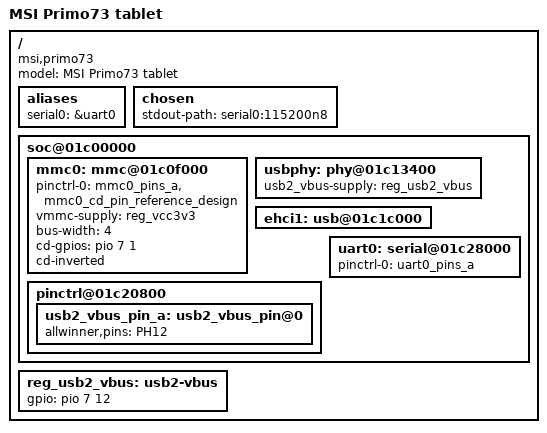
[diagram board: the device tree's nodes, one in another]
/*
 * Copyright 2014 Siarhei Siamashka <siarhei.siamashka@xxxxxxxxx>
 *
 * This file is dual-licensed: you can use it either under the terms
 * of the GPL or the X11 license, at your option. Note that this dual
 * licensing only applies to this file, and not this project as a
 * whole.
 *
 *  a) This library is free software; you can redistribute it and/or
 *     modify it under the terms of the GNU General Public License as
 *     published by the Free Software Foundation; either version 2 of the
 *     License, or (at your option) any later version.
 *
 *     This library is distributed in the hope that it will be useful,
 *     but WITHOUT ANY WARRANTY; without even the implied warranty of
 *     MERCHANTABILITY or FITNESS FOR A PARTICULAR PURPOSE.  See the
 *     GNU General Public License for more details.
 *
 *     You should have received a copy of the GNU General Public
 *     License along with this library; if not, write to the Free
 *     Software Foundation, Inc., 51 Franklin St, Fifth Floor, Boston,
 *     MA 02110-1301 USA
 *
 * Or, alternatively,
 *
 *  b) Permission is hereby granted, free of charge, to any person
 *     obtaining a copy of this software and associated documentation
 *     files (the "Software"), to deal in the Software without
 *     restriction, including without limitation the rights to use,
 *     copy, modify, merge, publish, distribute, sublicense, and/or
 *     sell copies of the Software, and to permit persons to whom the
 *     Software is furnished to do so, subject to the following
 *     conditions:
 *
 *     The above copyright notice and this permission notice shall be
 *     included in all copies or substantial portions of the Software.
 *
 *     THE SOFTWARE IS PROVIDED "AS IS", WITHOUT WARRANTY OF ANY KIND,
 *     EXPRESS OR IMPLIED, INCLUDING BUT NOT LIMITED TO THE WARRANTIES
 *     OF MERCHANTABILITY, FITNESS FOR A PARTICULAR PURPOSE AND
 *     NONINFRINGEMENT. IN NO EVENT SHALL THE AUTHORS OR COPYRIGHT
 *     HOLDERS BE LIABLE FOR ANY CLAIM, DAMAGES OR OTHER LIABILITY,
 *     WHETHER IN AN ACTION OF CONTRACT, TORT OR OTHERWISE, ARISING
 *     FROM, OUT OF OR IN CONNECTION WITH THE SOFTWARE OR THE USE OR
 *     OTHER DEALINGS IN THE SOFTWARE.
 */

/dts-v1/;
#include "sun7i-a20.dtsi"
#include "sunxi-common-regulators.dtsi"

/ {
	model = "MSI Primo73 tablet";
	compatible = "msi,primo73", "allwinner,sun7i-a20";

	aliases {
		serial0 = &uart0;
	};

	chosen {
		stdout-path = "serial0:115200n8";
	};

	soc@01c00000 {
		mmc0: mmc@01c0f000 {
			pinctrl-names = "default";
			pinctrl-0 = <&mmc0_pins_a>, <&mmc0_cd_pin_reference_design>;
			vmmc-supply = <&reg_vcc3v3>;
			bus-width = <4>;
			cd-gpios = <&pio 7 1 0>; /* PH1 */
			cd-inverted;
			status = "okay";
		};

		usbphy: phy@01c13400 {
			usb2_vbus-supply = <&reg_usb2_vbus>;
			status = "okay";
		};

		ehci1: usb@01c1c000 {
			/* rtl8188etv wifi is connected here */
			status = "okay";
		};

		pinctrl@01c20800 {
			usb2_vbus_pin_a: usb2_vbus_pin@0 {
				allwinner,pins = "PH12";
			};
		};

		uart0: serial@01c28000 {
			pinctrl-names = "default";
			pinctrl-0 = <&uart0_pins_a>;
			status = "okay";
		};
	};

	reg_usb2_vbus: usb2-vbus {
		gpio = <&pio 7 12 0>; /* PH12 */
		status = "okay";
	};
};
